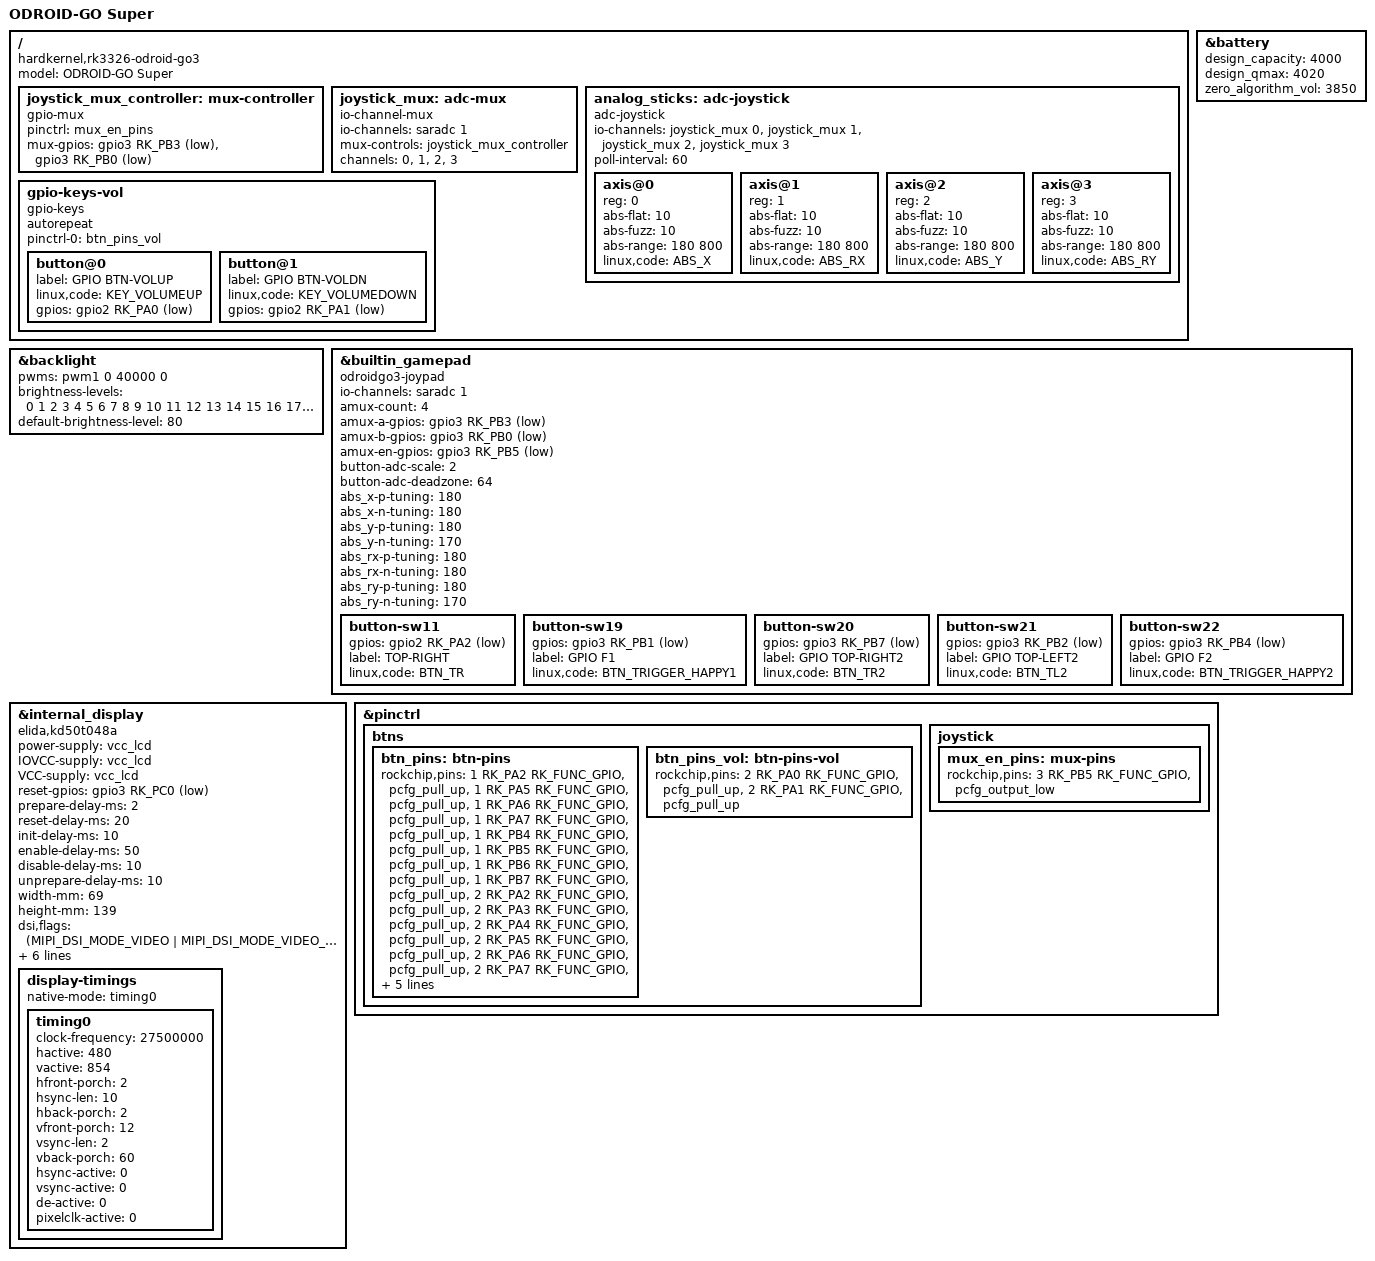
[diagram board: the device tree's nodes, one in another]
// SPDX-License-Identifier: (GPL-2.0+ OR MIT)
/*
 * Copyright (c) 2019 Hardkernel Co., Ltd
 * Copyright (c) 2020 Theobroma Systems Design und Consulting GmbH
 * Copyright (c) 2022 Maya Matuszczyk <maccraft123mc@gmail.com>
 */

/dts-v1/;
#include "rk3326-odroid-go.dtsi"

/ {
	model = "ODROID-GO Super";
	compatible = "hardkernel,rk3326-odroid-go3", "rockchip,rk3326";

	joystick_mux_controller: mux-controller {
		compatible = "gpio-mux";
		pinctrl = <&mux_en_pins>;
		#mux-control-cells = <0>;

		mux-gpios = <&gpio3 RK_PB3 GPIO_ACTIVE_LOW>,
			    <&gpio3 RK_PB0 GPIO_ACTIVE_LOW>;
	};

	joystick_mux: adc-mux {
		compatible = "io-channel-mux";
		io-channels = <&saradc 1>;
		io-channel-names = "parent";
		#io-channel-cells = <1>;

		mux-controls = <&joystick_mux_controller>;
		channels = "0", "1", "2", "3";
	};

	analog_sticks: adc-joystick {
		compatible = "adc-joystick";
		io-channels = <&joystick_mux 0>,
			      <&joystick_mux 1>,
			      <&joystick_mux 2>,
			      <&joystick_mux 3>;
		poll-interval = <60>;
		#address-cells = <1>;
		#size-cells = <0>;

		axis@0 {
			reg = <0>;
			abs-flat = <10>;
			abs-fuzz = <10>;
			abs-range = <180 800>;
			linux,code = <ABS_X>;
		};

		axis@1 {
			reg = <1>;
			abs-flat = <10>;
			abs-fuzz = <10>;
			abs-range = <180 800>;
			linux,code = <ABS_RX>;
		};

		axis@2 {
			reg = <2>;
			abs-flat = <10>;
			abs-fuzz = <10>;
			abs-range = <180 800>;
			linux,code = <ABS_Y>;
		};

		axis@3 {
			reg = <3>;
			abs-flat = <10>;
			abs-fuzz = <10>;
			abs-range = <180 800>;
			linux,code = <ABS_RY>;
		};
	};

	gpio-keys-vol {
		compatible = "gpio-keys";
		#address-cells = <1>;
		#size-cells = <0>;
		autorepeat;
		pinctrl-0 = <&btn_pins_vol>;
		pinctrl-names = "default";

		button@0 {
			label = "GPIO BTN-VOLUP";
			linux,code = <KEY_VOLUMEUP>;
			gpios = <&gpio2 RK_PA0 GPIO_ACTIVE_LOW>;
		};
		button@1 {
			label = "GPIO BTN-VOLDN";
			linux,code = <KEY_VOLUMEDOWN>;
			gpios = <&gpio2 RK_PA1 GPIO_ACTIVE_LOW>;
		};
	};
};

&backlight {
	pwms = <&pwm1 0 40000 0>;
	brightness-levels = <
		  0   1   2   3   4   5   6   7
		  8   9  10  11  12  13  14  15
		 16  17  18  19  20  21  22  23
		 24  25  26  27  28  29  30  31
		 32  33  34  35  36  37  38  39
		 40  41  42  43  44  45  46  47
		 48  49  50  51  52  53  54  55
		 56  57  58  59  60  61  62  63
		 64  65  66  67  68  69  70  71
		 72  73  74  75  76  77  78  79
		 80  81  82  83  84  85  86  87
		 88  89  90  91  92  93  94  95
		 96  97  98  99 100 101 102 103
		104 105 106 107 108 109 110 111
		112 113 114 115 116 117 118 119
		120 121 122 123 124 125 126 127
		128 129 130 131 132 133 134 135
		136 137 138 139 140 141 142 143
		144 145 146 147 148 149 150 151
		152 153 154 155 156 157 158 159
		160 >;
	default-brightness-level = <80>; /* default 50% */
};

/*
	- HCP775474ZC Battery
	Capacity : 3.7V 4000mAh, 14.8Wh
	Rated Voltage = 3.7V
	Charge Cut-Off Voltage : 4.25V
	Discharge Cut-Off Voltage : 3.0V
	Internal Impedance : 180 mOhm
	Charging Voltage : 4.2V
	Charging Voltage Max : 4.25V
	Sample resister : 10 mohm (R12)
*/
&battery {
	design_capacity = <4000>;
	design_qmax = <4020>;
	zero_algorithm_vol = <3850>;
};

/* f1 and f2 conflict with volume buttons */
/delete-node/ &btn_f1;
/delete-node/ &btn_f2;

&builtin_gamepad {
	compatible = "odroidgo3-joypad";

	/* Analog mux define */
	io-channel-names = "amux_adc";
	io-channels = <&saradc 1>;

	/* adc mux channel count */
	amux-count = <4>;
	/* adc mux select(a,b) gpio */
	amux-a-gpios = <&gpio3 RK_PB3 GPIO_ACTIVE_LOW>;
	amux-b-gpios = <&gpio3 RK_PB0 GPIO_ACTIVE_LOW>;
	/* adc mux enable gpio */
	amux-en-gpios = <&gpio3 RK_PB5 GPIO_ACTIVE_LOW>;

	/* adc calculate scale */
	button-adc-scale = <2>;

	/* adc deadzone range  */
	button-adc-deadzone = <64>;

	/*
	  Analog Stick data tuning value(precent)
	  p = positive direction, n = negative direction
	  report value = (real_adc_data * tuning_value) / 100
	*/
	abs_x-p-tuning = <180>;
	abs_x-n-tuning = <180>;

	abs_y-p-tuning = <180>;
	abs_y-n-tuning = <170>;

	abs_rx-p-tuning = <180>;
	abs_rx-n-tuning = <180>;

	abs_ry-p-tuning = <180>;
	abs_ry-n-tuning = <170>;

	button-sw11 {
		gpios = <&gpio2 RK_PA2 GPIO_ACTIVE_LOW>;
		label = "TOP-RIGHT";
		linux,code = <BTN_TR>;
	};
	button-sw19 {
		gpios = <&gpio3 RK_PB1 GPIO_ACTIVE_LOW>;
		label = "GPIO F1";
		linux,code = <BTN_TRIGGER_HAPPY1>;
	};
	button-sw20 {
		gpios = <&gpio3 RK_PB7 GPIO_ACTIVE_LOW>;
		label = "GPIO TOP-RIGHT2";
		linux,code = <BTN_TR2>;
	};
	button-sw21 {
		gpios = <&gpio3 RK_PB2 GPIO_ACTIVE_LOW>;
		label = "GPIO TOP-LEFT2";
		linux,code = <BTN_TL2>;
	};
	button-sw22 {
		gpios = <&gpio3 RK_PB4 GPIO_ACTIVE_LOW>;
		label = "GPIO F2";
		linux,code = <BTN_TRIGGER_HAPPY2>;
	};
};

&internal_display {
	compatible = "elida,kd50t048a", "simple-panel-dsi";

	/* RK817 LDO8 */
	power-supply = <&vcc_lcd>;
	IOVCC-supply = <&vcc_lcd>;
	VCC-supply = <&vcc_lcd>;

	/* LCD reset gpio GPIO3.C0 */
	reset-gpios = <&gpio3 RK_PC0 GPIO_ACTIVE_LOW>;

	prepare-delay-ms = <2>;
	reset-delay-ms = <20>;
	init-delay-ms = <10>;
	enable-delay-ms = <50>;
	disable-delay-ms = <10>;
	unprepare-delay-ms = <10>;

	/* LCD size */
	width-mm = <69>;
	height-mm = <139>;

	dsi,flags = <(MIPI_DSI_MODE_VIDEO           |
		      MIPI_DSI_MODE_VIDEO_BURST     |
		      MIPI_DSI_MODE_EOT_PACKET)>;

	dsi,format = <MIPI_DSI_FMT_RGB888>;
	dsi,lanes = <2>;

	/*
		- panel-init-sequence data description -
		  mipi_cmd, delay(ms), len, lcd_cmd, lcd_data...

		- mipi_cmd description -
		  05 : MIPI_DSI_SHORT_WRITE
		  15 : MIPI_DSI_SHORT_WRITE_PARAM
		  39 : MIPI_DSI_LONG_WRITE

		- ST7710S (Initialize sequence) -
		  01: Soft reset
		  11: Sleep out & 250ms wait
		  FF: Bank select CMD
		  C0: CMD2 Bank0 LNESET
		  C1: CMD2 Bank0 PORCTRL
		  C2: CMD2 Bank0 INVSEL
		  CC: ???
		  B0: CMD2 Bank0 PVGAMCTRL
		  B1: CMD2 Bank0 NVGAMCTRL
		  B0: CMD2 Bank1 VRHS
		  B1: CMD2 Bank1 VCOMS
		  B2: CMD2 Bank1 VGHSS
		  B3: CMD2 Bank1 TESTCMD
		  B5: CMD2 Bank1 VGLS
		  B7: CMD2 Bank1 PWRCTRL1
		  B8: CMD2 Bank1 PWRCTRL2
		  B9: CMD2 Bank1 PWRCTRL3
		  C1: CMD2 Bank1 PDR1
		  C2: CMD2 Bank1 PDR2
		  D0: CMD2 Bank1 MIPISET1
		  E0 ~ EF : GIP Setting
		  3A: Normal CMD COLMOD
		  53: Normal CMD WRCTRLD
		  55: Normal CMD WRCABC
		  5E: Normal CMD WRCABCMB
		  29: DisplayOn & 50ms wait
	*/

	panel-init-sequence = [
		05 05 01 01
		05 FA 01 11
		39 00 06 FF 77 01 00 00 10
		15 00 03 C0 E9 03
		15 00 03 C1 11 02
		15 00 03 C2 31 08
		15 00 02 CC 10
		39 00 11 B0 00 0D 14 0D 10 05 02 08
		            08 1E 05 13 11 A3 29 18
		39 00 11 B1 00 0C 14 0C 10 05 03 08
		            07 20 05 13 11 A4 29 18
		39 00 06 FF 77 01 00 00 11
		15 00 02 B0 6C
		15 00 02 B1 43
		15 00 02 B2 07
		15 00 02 B3 80
		15 00 02 B5 47
		15 00 02 B7 85
		15 00 02 B8 20
		15 00 02 B9 10
		15 00 02 C1 78
		15 00 02 C3 78
		15 FA 02 D0 88
		39 00 04 E0 00 00 02
		39 00 0C E1 08 00 0A 00 07 00 09 00 00 33 33
		39 00 0F E2 00 00 00 00 00 00 00 00 00 00 00 00 00 00
		39 00 05 E3 00 00 33 33
		15 00 03 E4 44 44
		39 00 11 E5 0E 60 A0 A0 10 60 A0 A0
		            0A 60 A0 A0 0C 60 A0 A0
		39 00 05 E6 00 00 33 33
		15 00 03 E7 44 44
		39 00 11 E8 0D 60 A0 A0 0F 60 A0 A0
		            09 60 A0 A0 0B 60 A0 A0
		39 00 08 EB 02 01 E4 E4 44 00 40
		15 00 03 EC 02 01
		39 00 11 ED AB 89 76 54 01 FF FF FF
		            FF FF FF 10 45 67 98 BA
		39 00 06 FF 77 01 00 00 00
		15 00 02 3A 70
		15 00 02 53 EC
		15 00 02 55 B3
		15 00 02 5E FF
		05 32 01 29
	];

	/* 28: DisplayOff */
	/* 10: SleepIn */
	panel-exit-sequence = [
		05 00 01 28
		05 00 01 10
	];

	display-timings {
		native-mode = <&timing0>;

		timing0: timing0 {
			clock-frequency = <27500000>;
			hactive = <480>;
			vactive = <854>;

			hfront-porch = <2>;
			hsync-len = <10>;
			hback-porch = <2>;
			vfront-porch = <12>;
			vsync-len = <2>;
			vback-porch = <60>;
			hsync-active = <0>;
			vsync-active = <0>;
			de-active = <0>;
			pixelclk-active = <0>;
		};
	};
};

&pinctrl {
	btns {
		btn_pins: btn-pins {
			rockchip,pins = <1 RK_PA2 RK_FUNC_GPIO &pcfg_pull_up>,
					<1 RK_PA5 RK_FUNC_GPIO &pcfg_pull_up>,
					<1 RK_PA6 RK_FUNC_GPIO &pcfg_pull_up>,
					<1 RK_PA7 RK_FUNC_GPIO &pcfg_pull_up>,
					<1 RK_PB4 RK_FUNC_GPIO &pcfg_pull_up>,
					<1 RK_PB5 RK_FUNC_GPIO &pcfg_pull_up>,
					<1 RK_PB6 RK_FUNC_GPIO &pcfg_pull_up>,
					<1 RK_PB7 RK_FUNC_GPIO &pcfg_pull_up>,
					<2 RK_PA2 RK_FUNC_GPIO &pcfg_pull_up>,
					<2 RK_PA3 RK_FUNC_GPIO &pcfg_pull_up>,
					<2 RK_PA4 RK_FUNC_GPIO &pcfg_pull_up>,
					<2 RK_PA5 RK_FUNC_GPIO &pcfg_pull_up>,
					<2 RK_PA6 RK_FUNC_GPIO &pcfg_pull_up>,
					<2 RK_PA7 RK_FUNC_GPIO &pcfg_pull_up>,
					<3 RK_PB1 RK_FUNC_GPIO &pcfg_pull_up>,
					<3 RK_PB2 RK_FUNC_GPIO &pcfg_pull_up>,
					<3 RK_PB4 RK_FUNC_GPIO &pcfg_pull_up>,
					<3 RK_PB7 RK_FUNC_GPIO &pcfg_pull_up>;
		};
		btn_pins_vol: btn-pins-vol {
			rockchip,pins = <2 RK_PA0 RK_FUNC_GPIO &pcfg_pull_up>,
					<2 RK_PA1 RK_FUNC_GPIO &pcfg_pull_up>;
		};
	};

	joystick {
		mux_en_pins: mux-pins {
			rockchip,pins = <3 RK_PB5 RK_FUNC_GPIO &pcfg_output_low>;
		};
	};
};
